# MB9BF32xS register map
File version: 1.0
CPU: 
Registers are 8-bit, read-write, reset 0x0 unless marked. A register's access mark holds for its fields unless they carry their own. Offsets are from the block's base; [hi:lo] are bit positions; {n}, {i} and the like mark numbered series; 'fields as' and 'values as' point back to an identical list.

## GPIO — peripheral GPIO
Base 0x40033000
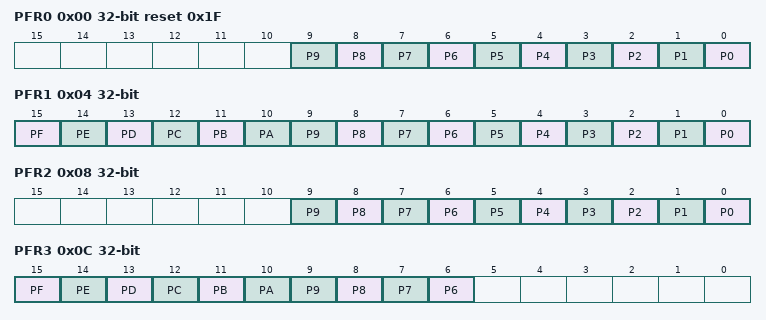
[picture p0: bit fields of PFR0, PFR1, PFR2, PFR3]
0x00 PFR0 32-bit reset 0x1F
  [n] P{n} (n=0..9)
0x04 PFR1 32-bit
  [15] PF, [14] PE, [13] PD, [12] PC, [11] PB, [10] PA, [n] P{n} (n=0..9)
0x08 PFR2 32-bit
  [n] P{n} (n=0..9)
0x0C PFR3 32-bit
  [15] PF, [14] PE, [13] PD, [12] PC, [11] PB, [10] PA, [n] P{n} (n=6..9)
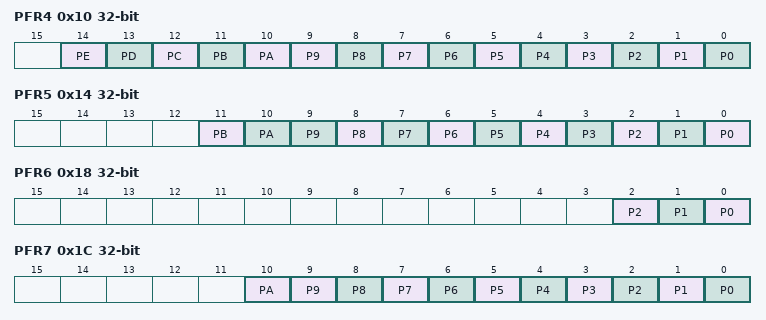
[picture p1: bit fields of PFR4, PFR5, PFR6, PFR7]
0x10 PFR4 32-bit
  [14] PE, [13] PD, [12] PC, [11] PB, [10] PA, [n] P{n} (n=0..9)
0x14 PFR5 32-bit
  [11] PB, [10] PA, [n] P{n} (n=0..9)
0x18 PFR6 32-bit
  [2] P2, [1] P1, [0] P0
0x1C PFR7 32-bit
  [10] PA, [n] P{n} (n=0..9)
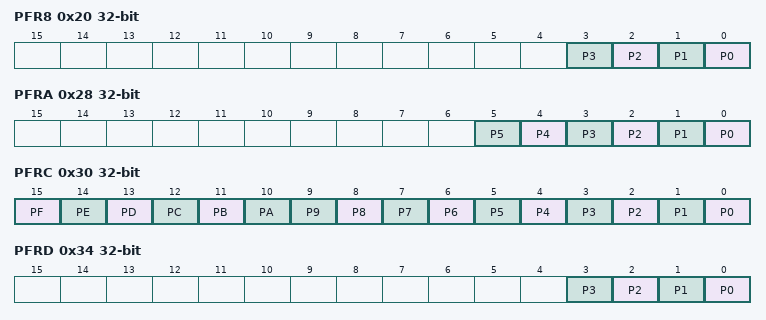
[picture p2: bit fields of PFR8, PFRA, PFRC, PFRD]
0x20 PFR8 32-bit
  [n] P{n} (n=0..3)
0x24 PFR9 32-bit reset not defined
0x28 PFRA 32-bit
  [n] P{n} (n=0..5)
0x2C PFRB 32-bit reset not defined
0x30 PFRC 32-bit
  fields as PFR1
0x34 PFRD 32-bit
  [n] P{n} (n=0..3)
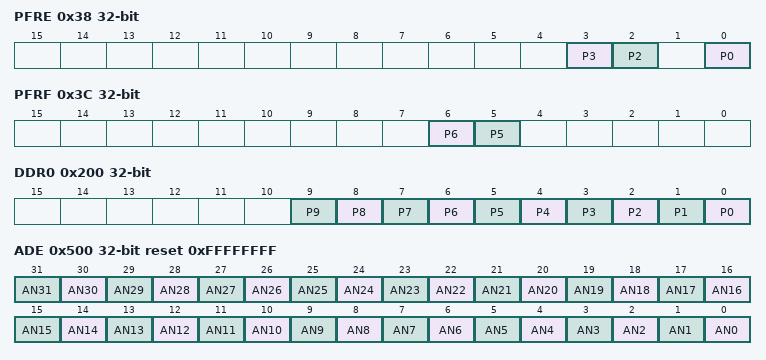
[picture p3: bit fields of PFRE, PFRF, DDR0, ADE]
0x38 PFRE 32-bit (reset mask 0xB)
  [3] P3, [2] P2, [0] P0
0x3C PFRF 32-bit
  [6] P6, [5] P5
{0x100+4i} PCR{i} 32-bit reset not defined (i=0..9)
0x128 PCRA 32-bit reset not defined
0x12C PCRB 32-bit reset not defined
0x130 PCRC 32-bit reset not defined
0x134 PCRD 32-bit reset not defined
0x138 PCRE 32-bit reset not defined
0x13C PCRF 32-bit reset not defined
0x200 DDR0 32-bit
  [n] P{n} (n=0..9)
{0x200+4i} DDR{i} 32-bit reset not defined (i=1..9)
0x228 DDRA 32-bit reset not defined
0x22C DDRB 32-bit reset not defined
0x230 DDRC 32-bit reset not defined
0x234 DDRD 32-bit reset not defined
0x238 DDRE 32-bit reset not defined
0x23C DDRF 32-bit reset not defined
{0x300+4i} PDIR{i} 32-bit reset not defined (i=0..9)
0x328 PDIRA 32-bit reset not defined
0x32C PDIRB 32-bit reset not defined
0x330 PDIRC 32-bit reset not defined
0x334 PDIRD 32-bit reset not defined
0x338 PDIRE 32-bit reset not defined
0x33C PDIRF 32-bit reset not defined
{0x400+4i} PDOR{i} 32-bit reset not defined (i=0..9)
0x428 PDORA 32-bit reset not defined
0x42C PDORB 32-bit reset not defined
0x430 PDORC 32-bit reset not defined
0x434 PDORD 32-bit reset not defined
0x438 PDORE 32-bit reset not defined
0x43C PDORF 32-bit reset not defined
0x500 ADE 32-bit reset 0xFFFFFFFF
  [n] AN{n} (n=0..31)
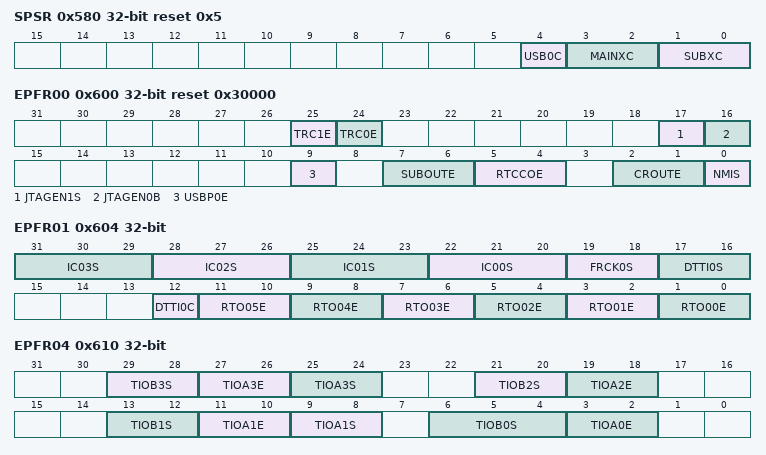
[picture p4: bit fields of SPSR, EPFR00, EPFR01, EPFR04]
0x580 SPSR 32-bit reset 0x5
  [4] USB0C, [3:2] MAINXC, [1:0] SUBXC
0x600 EPFR00 32-bit reset 0x30000 (reset mask 0x303002F7)
  [25] TRC1E, [24] TRC0E, [17] JTAGEN1S, [16] JTAGEN0B, [9] USBP0E, [7:6] SUBOUTE, [5:4] RTCCOE, [2:1] CROUTE, [0] NMIS
0x604 EPFR01 32-bit
  [3n+22:3n+20] IC{n:02}S (n=0..3), [19:18] FRCK0S, [17:16] DTTI0S, [12] DTTI0C, [2n+1:2n] RTO{n:02}E (n=0..5)
0x608 EPFR02 32-bit reset not defined
0x60C EPFR03 32-bit reset not defined
0x610 EPFR04 32-bit
  [29:28] TIOB3S, [8n+3:8n+2] TIOA{n}E (n=0..3), [25:24] TIOA3S, [21:20] TIOB2S, [13:12] TIOB1S, [9:8] TIOA1S, [6:4] TIOB0S
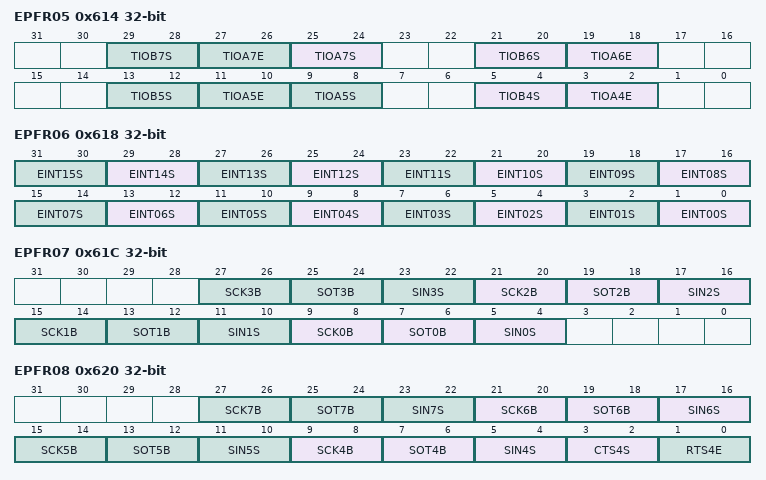
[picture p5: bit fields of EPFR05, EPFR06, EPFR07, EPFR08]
0x614 EPFR05 32-bit
  [8n-27:8n-28] TIOB{n}S (n=4..7), [8n-29:8n-30] TIOA{n}E (n=4..7), [25:24] TIOA7S, [9:8] TIOA5S
0x618 EPFR06 32-bit
  [2n+1:2n] EINT{n:02}S (n=0..15)
0x61C EPFR07 32-bit
  [6n+9:6n+8] SCK{n}B (n=0..3), [6n+7:6n+6] SOT{n}B (n=0..3), [6n+5:6n+4] SIN{n}S (n=0..3)
0x620 EPFR08 32-bit
  [6n-15:6n-16] SCK{n}B (n=4..7), [6n-17:6n-18] SOT{n}B (n=4..7), [6n-19:6n-20] SIN{n}S (n=4..7), [3:2] CTS4S, [1:0] RTS4E
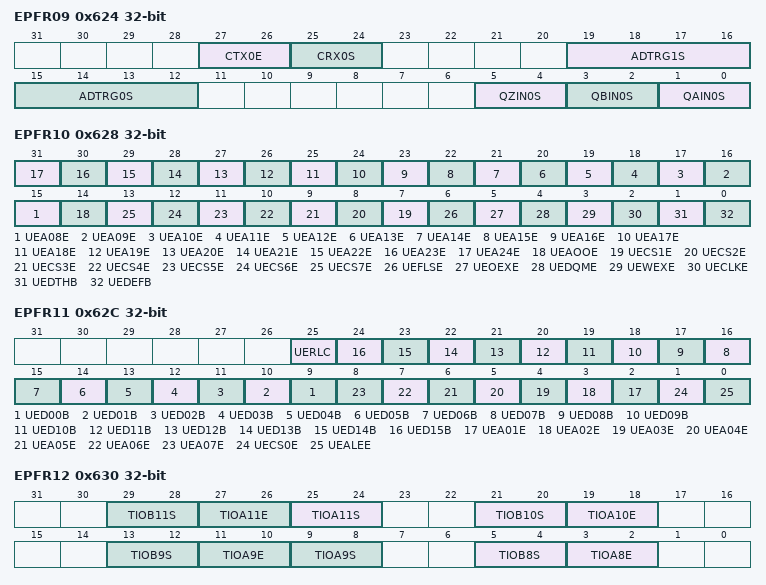
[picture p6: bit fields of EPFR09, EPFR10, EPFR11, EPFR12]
0x624 EPFR09 32-bit
  [27:26] CTX0E, [25:24] CRX0S, [19:16] ADTRG1S, [15:12] ADTRG0S, [5:4] QZIN0S, [3:2] QBIN0S, [1:0] QAIN0S
0x628 EPFR10 32-bit
  [n+7] UEA{n:02}E (n=8..24), [14] UEAOOE, [n+6] UECS{n}E (n=1..7), [6] UEFLSE, [5] UEOEXE, [4] UEDQME, [3] UEWEXE, [2] UECLKE, [1] UEDTHB, [0] UEDEFB
0x62C EPFR11 32-bit
  [25] UERLC, [n+9] UED{n:02}B (n=0..15), [n+1] UEA{n:02}E (n=1..7), [1] UECS0E, [0] UEALEE
0x630 EPFR12 32-bit
  [8n-59:8n-60] TIOB{n}S (n=8..11), [8n-61:8n-62] TIOA{n}E (n=8..11), [25:24] TIOA11S, [9:8] TIOA9S
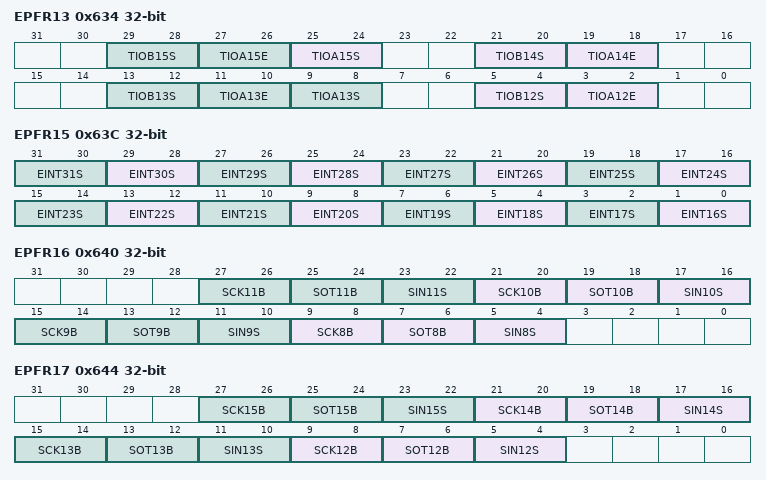
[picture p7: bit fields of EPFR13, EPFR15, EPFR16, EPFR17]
0x634 EPFR13 32-bit
  [8n-91:8n-92] TIOB{n}S (n=12..15), [8n-93:8n-94] TIOA{n}E (n=12..15), [25:24] TIOA15S, [9:8] TIOA13S
0x638 EPFR14 32-bit reset not defined
0x63C EPFR15 32-bit
  [2n-31:2n-32] EINT{n}S (n=16..31)
0x640 EPFR16 32-bit
  [6n-39:6n-40] SCK{n}B (n=8..11), [6n-41:6n-42] SOT{n}B (n=8..11), [6n-43:6n-44] SIN{n}S (n=8..11)
0x644 EPFR17 32-bit
  [6n-63:6n-64] SCK{n}B (n=12..15), [6n-65:6n-66] SOT{n}B (n=12..15), [6n-67:6n-68] SIN{n}S (n=12..15)
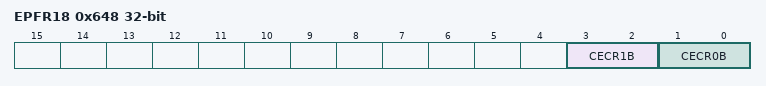
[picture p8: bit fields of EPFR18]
0x648 EPFR18 32-bit
  [3:2] CECR1B, [1:0] CECR0B
{0x700+4i} PZR{i} 32-bit reset not defined (i=0..9)
0x728 PZRA 32-bit reset not defined
0x72C PZRB 32-bit reset not defined
0x730 PZRC 32-bit reset not defined
0x734 PZRD 32-bit reset not defined
0x738 PZRE 32-bit reset not defined
0x73C PZRF 32-bit reset not defined
